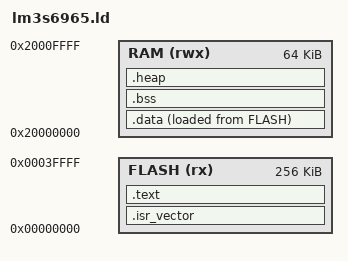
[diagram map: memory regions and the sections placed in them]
MEMORY
{
    FLASH (rx)  : ORIGIN = 0x00000000, LENGTH = 256K
    RAM   (rwx) : ORIGIN = 0x20000000, LENGTH = 64K
}

_estack = ORIGIN(RAM) + LENGTH(RAM);

SECTIONS
{
    .isr_vector :
    {
        . = ALIGN(4);
        KEEP(*(.isr_vector))
        . = ALIGN(4);
    } > FLASH

    .text :
    {
        . = ALIGN(4);
        *(.text)
        *(.text*)
        *(.rodata)
        *(.rodata*)
        . = ALIGN(4);
        _etext = .;
    } > FLASH

    .data :
    {
        . = ALIGN(4);
        _sdata = .;
        *(.data)
        *(.data*)
        . = ALIGN(4);
        _edata = .;
    } > RAM AT > FLASH

    _sidata = LOADADDR(.data);

    .bss :
    {
        . = ALIGN(4);
        _sbss = .;
        *(.bss)
        *(.bss*)
        *(COMMON)
        . = ALIGN(4);
        _ebss = .;
    } > RAM

    .heap :
    {
        . = ALIGN(4);
        _heap_start = .;
        . = . + 0x1000;
        . = ALIGN(4);
    } > RAM
}
